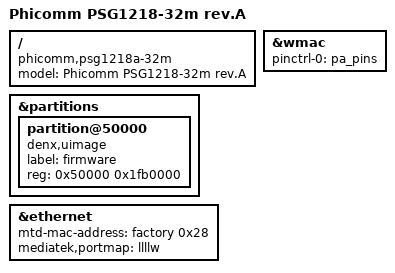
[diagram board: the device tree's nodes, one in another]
#include "mt7620a_phicomm_k2x.dtsi"

/ {
	compatible = "phicomm,psg1218a-32m", "phicomm,psg1218", "ralink,mt7620a-soc";
	model = "Phicomm PSG1218-32m rev.A";
};

&partitions {
	partition@50000 {
		compatible = "denx,uimage";
		label = "firmware";
		reg = <0x50000 0x1fb0000>;
	};
};

&ethernet {
	mtd-mac-address = <&factory 0x28>;

	mediatek,portmap = "llllw";
};

&wmac {
	pinctrl-names = "default";
	pinctrl-0 = <&pa_pins>;
};
